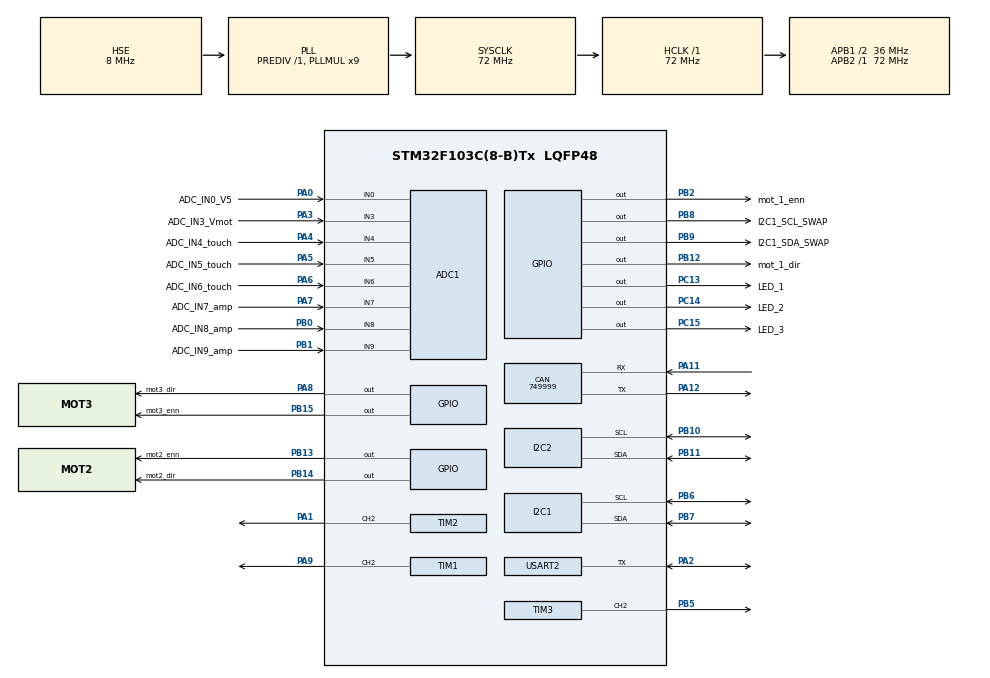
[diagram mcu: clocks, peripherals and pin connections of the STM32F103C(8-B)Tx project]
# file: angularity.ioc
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ADC1.Channel-0\#ChannelRegularConversion=ADC_CHANNEL_TEMPSENSOR
ADC1.NbrOfConversionFlag=1
ADC1.Rank-0\#ChannelRegularConversion=1
ADC1.SamplingTime-0\#ChannelRegularConversion=ADC_SAMPLETIME_1CYCLE_5
ADC1.master=1
CAN.BS1=CAN_BS1_1TQ
CAN.BS2=CAN_BS2_1TQ
CAN.CalculateBaudRate=749999
CAN.CalculateTimeBit=1333
CAN.CalculateTimeQuantum=444.44444444444446
Dma.ADC1.3.Direction=DMA_PERIPH_TO_MEMORY
Dma.ADC1.3.Instance=DMA1_Channel1
Dma.ADC1.3.MemDataAlignment=DMA_MDATAALIGN_HALFWORD
Dma.ADC1.3.MemInc=DMA_MINC_ENABLE
Dma.ADC1.3.Mode=DMA_NORMAL
Dma.ADC1.3.PeriphDataAlignment=DMA_PDATAALIGN_HALFWORD
Dma.ADC1.3.PeriphInc=DMA_PINC_DISABLE
Dma.ADC1.3.Priority=DMA_PRIORITY_LOW
Dma.Request0=TIM2_UP
Dma.Request1=USART2_RX
Dma.Request2=USART2_TX
Dma.Request3=ADC1
Dma.TIM2_UP.0.Direction=DMA_MEMORY_TO_PERIPH
Dma.TIM2_UP.0.Instance=DMA1_Channel2
Dma.TIM2_UP.0.MemDataAlignment=DMA_MDATAALIGN_HALFWORD
Dma.TIM2_UP.0.MemInc=DMA_MINC_ENABLE
Dma.TIM2_UP.0.Mode=DMA_NORMAL
Dma.TIM2_UP.0.PeriphDataAlignment=DMA_PDATAALIGN_HALFWORD
Dma.TIM2_UP.0.PeriphInc=DMA_PINC_DISABLE
Dma.TIM2_UP.0.Priority=DMA_PRIORITY_LOW
Dma.USART2_RX.1.Direction=DMA_PERIPH_TO_MEMORY
Dma.USART2_RX.1.Instance=DMA1_Channel6
Dma.USART2_RX.1.MemDataAlignment=DMA_MDATAALIGN_BYTE
Dma.USART2_RX.1.MemInc=DMA_MINC_ENABLE
Dma.USART2_RX.1.Mode=DMA_NORMAL
Dma.USART2_RX.1.PeriphDataAlignment=DMA_PDATAALIGN_BYTE
Dma.USART2_RX.1.PeriphInc=DMA_PINC_DISABLE
Dma.USART2_RX.1.Priority=DMA_PRIORITY_LOW
Dma.USART2_TX.2.Direction=DMA_MEMORY_TO_PERIPH
Dma.USART2_TX.2.Instance=DMA1_Channel7
Dma.USART2_TX.2.MemDataAlignment=DMA_MDATAALIGN_BYTE
Dma.USART2_TX.2.MemInc=DMA_MINC_ENABLE
Dma.USART2_TX.2.Mode=DMA_NORMAL
Dma.USART2_TX.2.PeriphDataAlignment=DMA_PDATAALIGN_BYTE
Dma.USART2_TX.2.PeriphInc=DMA_PINC_DISABLE
Dma.USART2_TX.2.Priority=DMA_PRIORITY_LOW
FREERTOS.Tasks01=defaultTask,24,128,StartDefaultTask,Default,NULL,Dynamic,NULL,NULL
FREERTOS.configUSE_NEWLIB_REENTRANT=1
I2C1.I2C_Mode=I2C_Fast
I2C2.I2C_Mode=I2C_Fast
Mcu.Family=STM32F1
Mcu.Name=STM32F103C(8-B)Tx
Mcu.Package=LQFP48
NVIC.DMA1_Channel1_IRQn=true\:5\:0\:false\:false\:true\:true\:false\:true\:true
NVIC.DMA1_Channel2_IRQn=true\:5\:0\:false\:false\:true\:true\:false\:true\:true
NVIC.DMA1_Channel6_IRQn=true\:5\:0\:false\:false\:true\:true\:false\:true\:true
NVIC.DMA1_Channel7_IRQn=true\:5\:0\:false\:false\:true\:true\:false\:true\:true
NVIC.PriorityGroup=NVIC_PRIORITYGROUP_4
PA0-WKUP.GPIO_Label=ADC_IN0_V5
PA0-WKUP.Signal=ADCx_IN0
PA1.GPIO_Speed=GPIO_SPEED_FREQ_LOW
PA1.Signal=S_TIM2_CH2
PA11.Mode=CAN_Activate
PA11.Signal=CAN_RX
PA12.Mode=CAN_Activate
PA12.Signal=CAN_TX
PA13.Mode=Trace_Asynchronous_SW
PA13.Signal=SYS_JTMS-SWDIO
PA14.Mode=Trace_Asynchronous_SW
PA14.Signal=SYS_JTCK-SWCLK
PA2.Mode=Half_duplex(single_wire_mode)
PA2.Signal=USART2_TX
PA3.GPIO_Label=ADC_IN3_Vmot
PA3.Signal=ADCx_IN3
PA4.GPIO_Label=ADC_IN4_touch
PA4.Signal=ADCx_IN4
PA5.GPIO_Label=ADC_IN5_touch
PA5.Signal=ADCx_IN5
PA6.GPIO_Label=ADC_IN6_touch
PA6.Signal=ADCx_IN6
PA7.GPIO_Label=ADC_IN7_amp
PA7.Signal=ADCx_IN7
PA8.GPIO_Label=mot3_dir
PA8.Signal=GPIO_Output
PA9.Signal=S_TIM1_CH2
PB0.GPIO_Label=ADC_IN8_amp
PB0.Signal=ADCx_IN8
PB1.GPIO_Label=ADC_IN9_amp
PB1.Signal=ADCx_IN9
PB10.Mode=I2C
PB10.Signal=I2C2_SCL
PB11.Mode=I2C
PB11.Signal=I2C2_SDA
PB12.GPIO_Label=mot_1_dir
PB12.PinState=GPIO_PIN_RESET
PB12.Signal=GPIO_Output
PB13.GPIO_Label=mot2_enn
PB13.PinState=GPIO_PIN_SET
PB13.Signal=GPIO_Output
PB14.GPIO_Label=mot2_dir
PB14.Signal=GPIO_Output
PB15.GPIO_Label=mot3_enn
PB15.PinState=GPIO_PIN_SET
PB15.Signal=GPIO_Output
PB2.GPIO_Label=mot_1_enn
PB2.PinState=GPIO_PIN_SET
PB2.Signal=GPIO_Output
PB3.Mode=Trace_Asynchronous_SW
PB3.Signal=SYS_JTDO-TRACESWO
PB5.Signal=S_TIM3_CH2
PB6.Mode=I2C
PB6.Signal=I2C1_SCL
PB7.Mode=I2C
PB7.Signal=I2C1_SDA
PB8.GPIO_Label=I2C1_SCL_SWAP
PB8.GPIO_ModeDefaultOutputPP=GPIO_MODE_OUTPUT_OD
PB8.GPIO_PuPd=GPIO_NOPULL
PB8.PinState=GPIO_PIN_SET
PB8.Signal=GPIO_Output
PB9.GPIO_Label=I2C1_SDA_SWAP
PB9.GPIO_ModeDefaultOutputPP=GPIO_MODE_OUTPUT_OD
PB9.GPIO_PuPd=GPIO_NOPULL
PB9.PinState=GPIO_PIN_SET
PB9.Signal=GPIO_Output
PC13-TAMPER-RTC.GPIO_Label=LED_1
PC13-TAMPER-RTC.GPIO_ModeDefaultOutputPP=GPIO_MODE_OUTPUT_OD
PC13-TAMPER-RTC.GPIO_PuPd=GPIO_NOPULL
PC13-TAMPER-RTC.PinState=GPIO_PIN_SET
PC13-TAMPER-RTC.Signal=GPIO_Output
PC14-OSC32_IN.GPIO_Label=LED_2
PC14-OSC32_IN.GPIO_ModeDefaultOutputPP=GPIO_MODE_OUTPUT_OD
PC14-OSC32_IN.GPIO_PuPd=GPIO_NOPULL
PC14-OSC32_IN.PinState=GPIO_PIN_SET
PC14-OSC32_IN.Signal=GPIO_Output
PC15-OSC32_OUT.GPIO_Label=LED_3
PC15-OSC32_OUT.GPIO_ModeDefaultOutputPP=GPIO_MODE_OUTPUT_OD
PC15-OSC32_OUT.GPIO_PuPd=GPIO_NOPULL
PC15-OSC32_OUT.PinState=GPIO_PIN_SET
PC15-OSC32_OUT.Signal=GPIO_Output
PD0-OSC_IN.Mode=HSE-External-Oscillator
PD0-OSC_IN.Signal=RCC_OSC_IN
PD1-OSC_OUT.Mode=HSE-External-Oscillator
PD1-OSC_OUT.Signal=RCC_OSC_OUT
ProjectManager.HeapSize=0x200
ProjectManager.StackSize=0x400
ProjectManager.TargetToolchain=STM32CubeIDE
RCC.ADCPresc=RCC_ADCPCLK2_DIV6
RCC.AHBFreq_Value=72000000
RCC.APB1CLKDivider=RCC_HCLK_DIV2
RCC.APB1Freq_Value=36000000
RCC.APB1TimFreq_Value=72000000
RCC.APB2Freq_Value=72000000
RCC.APB2TimFreq_Value=72000000
RCC.HCLKFreq_Value=72000000
RCC.PLLMUL=RCC_PLL_MUL9
RCC.PLLSourceVirtual=RCC_PLLSOURCE_HSE
RCC.RCC_MCOSource=RCC_MCO1SOURCE_HSE
RCC.SYSCLKFreq_VALUE=72000000
RCC.SYSCLKSource=RCC_SYSCLKSOURCE_PLLCLK
RCC.USBFreq_Value=72000000
SH.ADCx_IN0.0=ADC1_IN0,IN0
SH.ADCx_IN3.0=ADC1_IN3,IN3
SH.ADCx_IN4.0=ADC1_IN4,IN4
SH.ADCx_IN5.0=ADC1_IN5,IN5
SH.ADCx_IN6.0=ADC1_IN6,IN6
SH.ADCx_IN7.0=ADC1_IN7,IN7
SH.ADCx_IN8.0=ADC1_IN8,IN8
SH.ADCx_IN9.0=ADC1_IN9,IN9
SH.S_TIM1_CH2.0=TIM1_CH2,Output Compare2 CH2
SH.S_TIM2_CH2.0=TIM2_CH2,Output Compare2 CH2
SH.S_TIM3_CH2.0=TIM3_CH2,Output Compare2 CH2
TIM1.Channel-Output\ Compare2\ CH2=TIM_CHANNEL_2
TIM2.Channel-Output\ Compare2\ CH2=TIM_CHANNEL_2
TIM3.Channel-Output\ Compare2\ CH2=TIM_CHANNEL_2
USART2.VirtualMode=VM_ASYNC
VP_ADC1_TempSens_Input.Mode=IN-TempSens
VP_ADC1_Vref_Input.Mode=IN-Vrefint
VP_FREERTOS_VS_CMSIS_V2.Mode=CMSIS_V2
board=custom

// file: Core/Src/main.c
/* USER CODE BEGIN Header */
/**
  ******************************************************************************
  * @file           : main.c
  * @brief          : Main program body
  ******************************************************************************
  * @attention
  *
  * Copyright (c) 2023 STMicroelectronics.
  * All rights reserved.
  *
  * This software is licensed under terms that can be found in the LICENSE file
  * in the root directory of this software component.
  * If no LICENSE file comes with this software, it is provided AS-IS.
  *
  ******************************************************************************
  */
/* USER CODE END Header */
#include "main.h"
#include "cmsis_os.h"

/* USER CODE BEGIN Includes */
#include "as5600.h"
/* USER CODE END Includes */

ADC_HandleTypeDef hadc1;
DMA_HandleTypeDef hdma_adc1;

CAN_HandleTypeDef hcan;

I2C_HandleTypeDef hi2c1;
I2C_HandleTypeDef hi2c2;

TIM_HandleTypeDef htim1;
TIM_HandleTypeDef htim2;
TIM_HandleTypeDef htim3;
DMA_HandleTypeDef hdma_tim2_up;

UART_HandleTypeDef huart2;
DMA_HandleTypeDef hdma_usart2_rx;
DMA_HandleTypeDef hdma_usart2_tx;

/* Definitions for defaultTask */
osThreadId_t defaultTaskHandle;
const osThreadAttr_t defaultTask_attributes = {
  .name = "defaultTask",
  .stack_size = 128 * 4,
  .priority = (osPriority_t) osPriorityNormal,
};

void SystemClock_Config(void);
static void MX_GPIO_Init(void);
static void MX_DMA_Init(void);
static void MX_ADC1_Init(void);
static void MX_CAN_Init(void);
static void MX_I2C1_Init(void);
static void MX_I2C2_Init(void);
static void MX_TIM1_Init(void);
static void MX_TIM2_Init(void);
static void MX_TIM3_Init(void);
static void MX_USART2_UART_Init(void);
void StartDefaultTask(void *argument);

int main(void)
{

  /* MCU Configuration--------------------------------------------------------*/

  /* Reset of all peripherals, Initializes the Flash interface and the Systick. */
  HAL_Init();

  /* Configure the system clock */
  SystemClock_Config();

  /* Initialize all configured peripherals */
  MX_GPIO_Init();
  MX_DMA_Init();
  MX_ADC1_Init();
  MX_CAN_Init();
  MX_I2C1_Init();
  MX_I2C2_Init();
  MX_TIM1_Init();
  MX_TIM2_Init();
  MX_TIM3_Init();
  MX_USART2_UART_Init();

  /* Init scheduler */
  osKernelInitialize();

  /* Create the thread(s) */
  /* creation of defaultTask */
  defaultTaskHandle = osThreadNew(StartDefaultTask, NULL, &defaultTask_attributes);

  /* Start scheduler */
  osKernelStart();
  /* We should never get here as control is now taken by the scheduler */
  /* Infinite loop */
  while (1)
  {

  }
}

void SystemClock_Config(void)
{
  RCC_OscInitTypeDef RCC_OscInitStruct = {0};
  RCC_ClkInitTypeDef RCC_ClkInitStruct = {0};
  RCC_PeriphCLKInitTypeDef PeriphClkInit = {0};

  /** Initializes the RCC Oscillators according to the specified parameters
  * in the RCC_OscInitTypeDef structure.
  */
  RCC_OscInitStruct.OscillatorType = RCC_OSCILLATORTYPE_HSE;
  RCC_OscInitStruct.HSEState = RCC_HSE_ON;
  RCC_OscInitStruct.HSEPredivValue = RCC_HSE_PREDIV_DIV1;
  RCC_OscInitStruct.HSIState = RCC_HSI_ON;
  RCC_OscInitStruct.PLL.PLLState = RCC_PLL_ON;
  RCC_OscInitStruct.PLL.PLLSource = RCC_PLLSOURCE_HSE;
  RCC_OscInitStruct.PLL.PLLMUL = RCC_PLL_MUL9;
  if (HAL_RCC_OscConfig(&RCC_OscInitStruct) != HAL_OK)
  {
    Error_Handler();
  }

  /** Initializes the CPU, AHB and APB buses clocks
  */
  RCC_ClkInitStruct.ClockType = RCC_CLOCKTYPE_HCLK|RCC_CLOCKTYPE_SYSCLK
                              |RCC_CLOCKTYPE_PCLK1|RCC_CLOCKTYPE_PCLK2;
  RCC_ClkInitStruct.SYSCLKSource = RCC_SYSCLKSOURCE_PLLCLK;
  RCC_ClkInitStruct.AHBCLKDivider = RCC_SYSCLK_DIV1;
  RCC_ClkInitStruct.APB1CLKDivider = RCC_HCLK_DIV2;
  RCC_ClkInitStruct.APB2CLKDivider = RCC_HCLK_DIV1;

  if (HAL_RCC_ClockConfig(&RCC_ClkInitStruct, FLASH_LATENCY_2) != HAL_OK)
  {
    Error_Handler();
  }
  PeriphClkInit.PeriphClockSelection = RCC_PERIPHCLK_ADC;
  PeriphClkInit.AdcClockSelection = RCC_ADCPCLK2_DIV6;
  if (HAL_RCCEx_PeriphCLKConfig(&PeriphClkInit) != HAL_OK)
  {
    Error_Handler();
  }
}

static void MX_ADC1_Init(void)
{

  ADC_ChannelConfTypeDef sConfig = {0};

  /** Common config
  */
  hadc1.Instance = ADC1;
  hadc1.Init.ScanConvMode = ADC_SCAN_DISABLE;
  hadc1.Init.ContinuousConvMode = DISABLE;
  hadc1.Init.DiscontinuousConvMode = DISABLE;
  hadc1.Init.ExternalTrigConv = ADC_SOFTWARE_START;
  hadc1.Init.DataAlign = ADC_DATAALIGN_RIGHT;
  hadc1.Init.NbrOfConversion = 1;
  if (HAL_ADC_Init(&hadc1) != HAL_OK)
  {
    Error_Handler();
  }

  /** Configure Regular Channel
  */
  sConfig.Channel = ADC_CHANNEL_TEMPSENSOR;
  sConfig.Rank = ADC_REGULAR_RANK_1;
  sConfig.SamplingTime = ADC_SAMPLETIME_1CYCLE_5;
  if (HAL_ADC_ConfigChannel(&hadc1, &sConfig) != HAL_OK)
  {
    Error_Handler();
  }

}

static void MX_CAN_Init(void)
{

  hcan.Instance = CAN1;
  hcan.Init.Prescaler = 16;
  hcan.Init.Mode = CAN_MODE_NORMAL;
  hcan.Init.SyncJumpWidth = CAN_SJW_1TQ;
  hcan.Init.TimeSeg1 = CAN_BS1_1TQ;
  hcan.Init.TimeSeg2 = CAN_BS2_1TQ;
  hcan.Init.TimeTriggeredMode = DISABLE;
  hcan.Init.AutoBusOff = DISABLE;
  hcan.Init.AutoWakeUp = DISABLE;
  hcan.Init.AutoRetransmission = DISABLE;
  hcan.Init.ReceiveFifoLocked = DISABLE;
  hcan.Init.TransmitFifoPriority = DISABLE;
  if (HAL_CAN_Init(&hcan) != HAL_OK)
  {
    Error_Handler();
  }

}

static void MX_I2C1_Init(void)
{

  hi2c1.Instance = I2C1;
  hi2c1.Init.ClockSpeed = 400000;
  hi2c1.Init.DutyCycle = I2C_DUTYCYCLE_2;
  hi2c1.Init.OwnAddress1 = 0;
  hi2c1.Init.AddressingMode = I2C_ADDRESSINGMODE_7BIT;
  hi2c1.Init.DualAddressMode = I2C_DUALADDRESS_DISABLE;
  hi2c1.Init.OwnAddress2 = 0;
  hi2c1.Init.GeneralCallMode = I2C_GENERALCALL_DISABLE;
  hi2c1.Init.NoStretchMode = I2C_NOSTRETCH_DISABLE;
  if (HAL_I2C_Init(&hi2c1) != HAL_OK)
  {
    Error_Handler();
  }

}

static void MX_I2C2_Init(void)
{

  hi2c2.Instance = I2C2;
  hi2c2.Init.ClockSpeed = 400000;
  hi2c2.Init.DutyCycle = I2C_DUTYCYCLE_2;
  hi2c2.Init.OwnAddress1 = 0;
  hi2c2.Init.AddressingMode = I2C_ADDRESSINGMODE_7BIT;
  hi2c2.Init.DualAddressMode = I2C_DUALADDRESS_DISABLE;
  hi2c2.Init.OwnAddress2 = 0;
  hi2c2.Init.GeneralCallMode = I2C_GENERALCALL_DISABLE;
  hi2c2.Init.NoStretchMode = I2C_NOSTRETCH_DISABLE;
  if (HAL_I2C_Init(&hi2c2) != HAL_OK)
  {
    Error_Handler();
  }

}

static void MX_TIM1_Init(void)
{

  TIM_MasterConfigTypeDef sMasterConfig = {0};
  TIM_OC_InitTypeDef sConfigOC = {0};
  TIM_BreakDeadTimeConfigTypeDef sBreakDeadTimeConfig = {0};

  htim1.Instance = TIM1;
  htim1.Init.Prescaler = 0;
  htim1.Init.CounterMode = TIM_COUNTERMODE_UP;
  htim1.Init.Period = 65535;
  htim1.Init.ClockDivision = TIM_CLOCKDIVISION_DIV1;
  htim1.Init.RepetitionCounter = 0;
  htim1.Init.AutoReloadPreload = TIM_AUTORELOAD_PRELOAD_DISABLE;
  if (HAL_TIM_OC_Init(&htim1) != HAL_OK)
  {
    Error_Handler();
  }
  sMasterConfig.MasterOutputTrigger = TIM_TRGO_RESET;
  sMasterConfig.MasterSlaveMode = TIM_MASTERSLAVEMODE_DISABLE;
  if (HAL_TIMEx_MasterConfigSynchronization(&htim1, &sMasterConfig) != HAL_OK)
  {
    Error_Handler();
  }
  sConfigOC.OCMode = TIM_OCMODE_TIMING;
  sConfigOC.Pulse = 0;
  sConfigOC.OCPolarity = TIM_OCPOLARITY_HIGH;
  sConfigOC.OCNPolarity = TIM_OCNPOLARITY_HIGH;
  sConfigOC.OCFastMode = TIM_OCFAST_DISABLE;
  sConfigOC.OCIdleState = TIM_OCIDLESTATE_RESET;
  sConfigOC.OCNIdleState = TIM_OCNIDLESTATE_RESET;
  if (HAL_TIM_OC_ConfigChannel(&htim1, &sConfigOC, TIM_CHANNEL_2) != HAL_OK)
  {
    Error_Handler();
  }
  sBreakDeadTimeConfig.OffStateRunMode = TIM_OSSR_DISABLE;
  sBreakDeadTimeConfig.OffStateIDLEMode = TIM_OSSI_DISABLE;
  sBreakDeadTimeConfig.LockLevel = TIM_LOCKLEVEL_OFF;
  sBreakDeadTimeConfig.DeadTime = 0;
  sBreakDeadTimeConfig.BreakState = TIM_BREAK_DISABLE;
  sBreakDeadTimeConfig.BreakPolarity = TIM_BREAKPOLARITY_HIGH;
  sBreakDeadTimeConfig.AutomaticOutput = TIM_AUTOMATICOUTPUT_DISABLE;
  if (HAL_TIMEx_ConfigBreakDeadTime(&htim1, &sBreakDeadTimeConfig) != HAL_OK)
  {
    Error_Handler();
  }
  HAL_TIM_MspPostInit(&htim1);

}

static void MX_TIM2_Init(void)
{

  TIM_MasterConfigTypeDef sMasterConfig = {0};
  TIM_OC_InitTypeDef sConfigOC = {0};

  htim2.Instance = TIM2;
  htim2.Init.Prescaler = 0;
  htim2.Init.CounterMode = TIM_COUNTERMODE_UP;
  htim2.Init.Period = 65535;
  htim2.Init.ClockDivision = TIM_CLOCKDIVISION_DIV1;
  htim2.Init.AutoReloadPreload = TIM_AUTORELOAD_PRELOAD_DISABLE;
  if (HAL_TIM_OC_Init(&htim2) != HAL_OK)
  {
    Error_Handler();
  }
  sMasterConfig.MasterOutputTrigger = TIM_TRGO_RESET;
  sMasterConfig.MasterSlaveMode = TIM_MASTERSLAVEMODE_DISABLE;
  if (HAL_TIMEx_MasterConfigSynchronization(&htim2, &sMasterConfig) != HAL_OK)
  {
    Error_Handler();
  }
  sConfigOC.OCMode = TIM_OCMODE_TIMING;
  sConfigOC.Pulse = 0;
  sConfigOC.OCPolarity = TIM_OCPOLARITY_HIGH;
  sConfigOC.OCFastMode = TIM_OCFAST_DISABLE;
  if (HAL_TIM_OC_ConfigChannel(&htim2, &sConfigOC, TIM_CHANNEL_2) != HAL_OK)
  {
    Error_Handler();
  }
  HAL_TIM_MspPostInit(&htim2);

}

static void MX_TIM3_Init(void)
{

  TIM_MasterConfigTypeDef sMasterConfig = {0};
  TIM_OC_InitTypeDef sConfigOC = {0};

  htim3.Instance = TIM3;
  htim3.Init.Prescaler = 0;
  htim3.Init.CounterMode = TIM_COUNTERMODE_UP;
  htim3.Init.Period = 65535;
  htim3.Init.ClockDivision = TIM_CLOCKDIVISION_DIV1;
  htim3.Init.AutoReloadPreload = TIM_AUTORELOAD_PRELOAD_DISABLE;
  if (HAL_TIM_OC_Init(&htim3) != HAL_OK)
  {
    Error_Handler();
  }
  sMasterConfig.MasterOutputTrigger = TIM_TRGO_RESET;
  sMasterConfig.MasterSlaveMode = TIM_MASTERSLAVEMODE_DISABLE;
  if (HAL_TIMEx_MasterConfigSynchronization(&htim3, &sMasterConfig) != HAL_OK)
  {
    Error_Handler();
  }
  sConfigOC.OCMode = TIM_OCMODE_TIMING;
  sConfigOC.Pulse = 0;
  sConfigOC.OCPolarity = TIM_OCPOLARITY_HIGH;
  sConfigOC.OCFastMode = TIM_OCFAST_DISABLE;
  if (HAL_TIM_OC_ConfigChannel(&htim3, &sConfigOC, TIM_CHANNEL_2) != HAL_OK)
  {
    Error_Handler();
  }
  HAL_TIM_MspPostInit(&htim3);

}

static void MX_USART2_UART_Init(void)
{

  huart2.Instance = USART2;
  huart2.Init.BaudRate = 115200;
  huart2.Init.WordLength = UART_WORDLENGTH_8B;
  huart2.Init.StopBits = UART_STOPBITS_1;
  huart2.Init.Parity = UART_PARITY_NONE;
  huart2.Init.Mode = UART_MODE_TX_RX;
  huart2.Init.HwFlowCtl = UART_HWCONTROL_NONE;
  huart2.Init.OverSampling = UART_OVERSAMPLING_16;
  if (HAL_HalfDuplex_Init(&huart2) != HAL_OK)
  {
    Error_Handler();
  }

}

static void MX_DMA_Init(void)
{

  /* DMA controller clock enable */
  __HAL_RCC_DMA1_CLK_ENABLE();

  /* DMA interrupt init */
  /* DMA1_Channel1_IRQn interrupt configuration */
  HAL_NVIC_SetPriority(DMA1_Channel1_IRQn, 5, 0);
  HAL_NVIC_EnableIRQ(DMA1_Channel1_IRQn);
  /* DMA1_Channel2_IRQn interrupt configuration */
  HAL_NVIC_SetPriority(DMA1_Channel2_IRQn, 5, 0);
  HAL_NVIC_EnableIRQ(DMA1_Channel2_IRQn);
  /* DMA1_Channel6_IRQn interrupt configuration */
  HAL_NVIC_SetPriority(DMA1_Channel6_IRQn, 5, 0);
  HAL_NVIC_EnableIRQ(DMA1_Channel6_IRQn);
  /* DMA1_Channel7_IRQn interrupt configuration */
  HAL_NVIC_SetPriority(DMA1_Channel7_IRQn, 5, 0);
  HAL_NVIC_EnableIRQ(DMA1_Channel7_IRQn);

}

static void MX_GPIO_Init(void)
{
  GPIO_InitTypeDef GPIO_InitStruct = {0};

  /* GPIO Ports Clock Enable */
  __HAL_RCC_GPIOC_CLK_ENABLE();
  __HAL_RCC_GPIOD_CLK_ENABLE();
  __HAL_RCC_GPIOA_CLK_ENABLE();
  __HAL_RCC_GPIOB_CLK_ENABLE();

  /*Configure GPIO pin Output Level */
  HAL_GPIO_WritePin(GPIOC, LED_1_Pin|LED_2_Pin|LED_3_Pin, GPIO_PIN_SET);

  /*Configure GPIO pin Output Level */
  HAL_GPIO_WritePin(GPIOB, mot_1_enn_Pin|mot2_enn_Pin|mot3_enn_Pin|I2C1_SCL_SWAP_Pin
                          |I2C1_SDA_SWAP_Pin, GPIO_PIN_SET);

  /*Configure GPIO pin Output Level */
  HAL_GPIO_WritePin(GPIOB, mot_1_dir_Pin|mot2_dir_Pin, GPIO_PIN_RESET);

  /*Configure GPIO pin Output Level */
  HAL_GPIO_WritePin(mot3_dir_GPIO_Port, mot3_dir_Pin, GPIO_PIN_RESET);

  /*Configure GPIO pins : LED_1_Pin LED_2_Pin LED_3_Pin */
  GPIO_InitStruct.Pin = LED_1_Pin|LED_2_Pin|LED_3_Pin;
  GPIO_InitStruct.Mode = GPIO_MODE_OUTPUT_OD;
  GPIO_InitStruct.Pull = GPIO_NOPULL;
  GPIO_InitStruct.Speed = GPIO_SPEED_FREQ_LOW;
  HAL_GPIO_Init(GPIOC, &GPIO_InitStruct);

  /*Configure GPIO pins : mot_1_enn_Pin mot_1_dir_Pin mot2_enn_Pin mot2_dir_Pin
                           mot3_enn_Pin */
  GPIO_InitStruct.Pin = mot_1_enn_Pin|mot_1_dir_Pin|mot2_enn_Pin|mot2_dir_Pin
                          |mot3_enn_Pin;
  GPIO_InitStruct.Mode = GPIO_MODE_OUTPUT_PP;
  GPIO_InitStruct.Pull = GPIO_NOPULL;
  GPIO_InitStruct.Speed = GPIO_SPEED_FREQ_LOW;
  HAL_GPIO_Init(GPIOB, &GPIO_InitStruct);

  /*Configure GPIO pin : mot3_dir_Pin */
  GPIO_InitStruct.Pin = mot3_dir_Pin;
  GPIO_InitStruct.Mode = GPIO_MODE_OUTPUT_PP;
  GPIO_InitStruct.Pull = GPIO_NOPULL;
  GPIO_InitStruct.Speed = GPIO_SPEED_FREQ_LOW;
  HAL_GPIO_Init(mot3_dir_GPIO_Port, &GPIO_InitStruct);

  /*Configure GPIO pins : I2C1_SCL_SWAP_Pin I2C1_SDA_SWAP_Pin */
  GPIO_InitStruct.Pin = I2C1_SCL_SWAP_Pin|I2C1_SDA_SWAP_Pin;
  GPIO_InitStruct.Mode = GPIO_MODE_OUTPUT_OD;
  GPIO_InitStruct.Pull = GPIO_NOPULL;
  GPIO_InitStruct.Speed = GPIO_SPEED_FREQ_LOW;
  HAL_GPIO_Init(GPIOB, &GPIO_InitStruct);

}

void StartDefaultTask(void *argument)
{
  /* USER CODE BEGIN 5 */
  task_alpha(argument);
  /* USER CODE END 5 */
}

void Error_Handler(void)
{
  __disable_irq();
  while (1)
  {
  }
}
